VERSION ""

NS_ :

BS_:

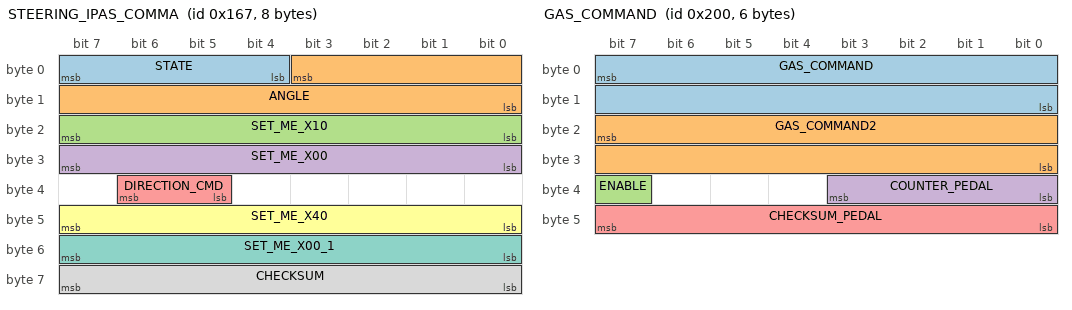
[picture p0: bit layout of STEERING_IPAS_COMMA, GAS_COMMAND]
BO_ 359 STEERING_IPAS_COMMA: 8 IPAS
 SG_ STATE : 7|4@0+ (1,0) [0|15] "" XXX
 SG_ ANGLE : 3|12@0- (1.5,0) [-510|510] "deg" XXX
 SG_ SET_ME_X10 : 23|8@0+ (1,0) [0|255] "" XXX
 SG_ SET_ME_X00 : 31|8@0+ (1,0) [0|255] "" XXX
 SG_ DIRECTION_CMD : 38|2@0+ (1,0) [0|3] "" XXX
 SG_ SET_ME_X40 : 47|8@0+ (1,0) [0|255] "" XXX
 SG_ SET_ME_X00_1 : 55|8@0+ (1,0) [0|255] "" XXX
 SG_ CHECKSUM : 63|8@0+ (1,0) [0|255] "" XXX

BO_ 512 GAS_COMMAND: 6 EON
 SG_ GAS_COMMAND : 7|16@0+ (0.159375,-75.555) [0|1] "" INTERCEPTOR
 SG_ GAS_COMMAND2 : 23|16@0+ (0.159375,-151.111) [0|1] "" INTERCEPTOR
 SG_ ENABLE : 39|1@0+ (1,0) [0|1] "" INTERCEPTOR
 SG_ COUNTER_PEDAL : 35|4@0+ (1,0) [0|15] "" INTERCEPTOR
 SG_ CHECKSUM_PEDAL : 47|8@0+ (1,0) [0|255] "" INTERCEPTOR

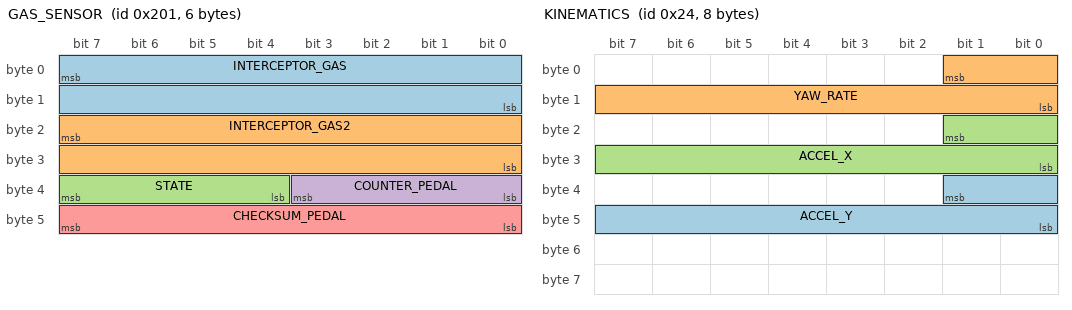
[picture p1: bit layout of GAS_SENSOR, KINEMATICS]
BO_ 513 GAS_SENSOR: 6 INTERCEPTOR
 SG_ INTERCEPTOR_GAS : 7|16@0+ (1,0) [0|1] "" EON
 SG_ INTERCEPTOR_GAS2 : 23|16@0+ (1,0) [0|1] "" EON
 SG_ STATE : 39|4@0+ (1,0) [0|15] "" EON
 SG_ COUNTER_PEDAL : 35|4@0+ (1,0) [0|15] "" EON
 SG_ CHECKSUM_PEDAL : 47|8@0+ (1,0) [0|255] "" EON

BO_ 35 SECONDARY_STEER_ANGLE: 8 XXX
 SG_ ZORRO_STEER : 7|24@0- (0.004901594652,0) [-500|500] "" XXX

BO_ 767 SDSU: 8 XXX
 SG_ FD_BUTTON : 7|1@0+ (1,0) [0|1] "" XXX

BO_ 36 KINEMATICS: 8 XXX
 SG_ ACCEL_Y : 33|10@0+ (0.03589,-18.375) [0|65535] "m/s^2" XXX
 SG_ YAW_RATE : 1|10@0+ (0.244,-125) [0|65535] "deg/s" XXX
 SG_ ACCEL_X : 17|10@0+ (0.03589,-18.375) [0|65535] "m/s^2" XXX

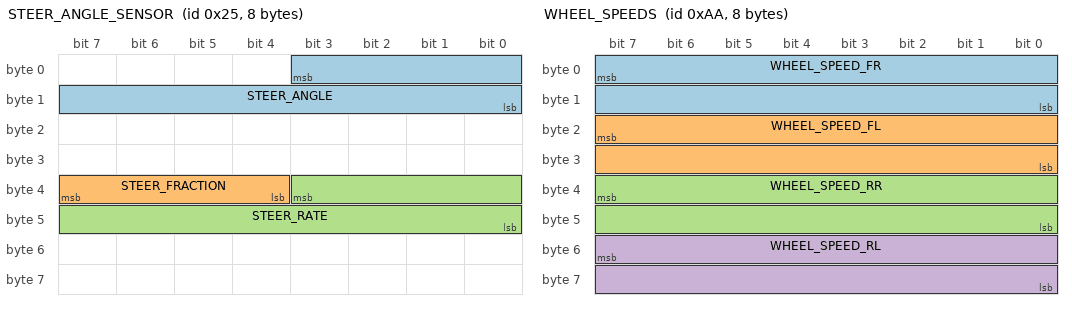
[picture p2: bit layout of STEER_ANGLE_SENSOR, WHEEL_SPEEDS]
BO_ 37 STEER_ANGLE_SENSOR: 8 XXX
 SG_ STEER_ANGLE : 3|12@0- (1.5,0) [-500|500] "deg" XXX
 SG_ STEER_FRACTION : 39|4@0- (0.1,0) [-0.7|0.7] "deg" XXX
 SG_ STEER_RATE : 35|12@0- (1,0) [-2000|2000] "deg/s" XXX

BO_ 166 BRAKE: 8 XXX
 SG_ BRAKE_AMOUNT : 7|8@0+ (1,0) [0|255] "" XXX
 SG_ BRAKE_PEDAL : 23|8@0+ (1,0) [0|255] "" XXX

BO_ 170 WHEEL_SPEEDS: 8 XXX
 SG_ WHEEL_SPEED_FR : 7|16@0+ (0.01,-67.67) [0|250] "km/h" XXX
 SG_ WHEEL_SPEED_FL : 23|16@0+ (0.01,-67.67) [0|250] "km/h" XXX
 SG_ WHEEL_SPEED_RR : 39|16@0+ (0.01,-67.67) [0|250] "km/h" XXX
 SG_ WHEEL_SPEED_RL : 55|16@0+ (0.01,-67.67) [0|250] "km/h" XXX

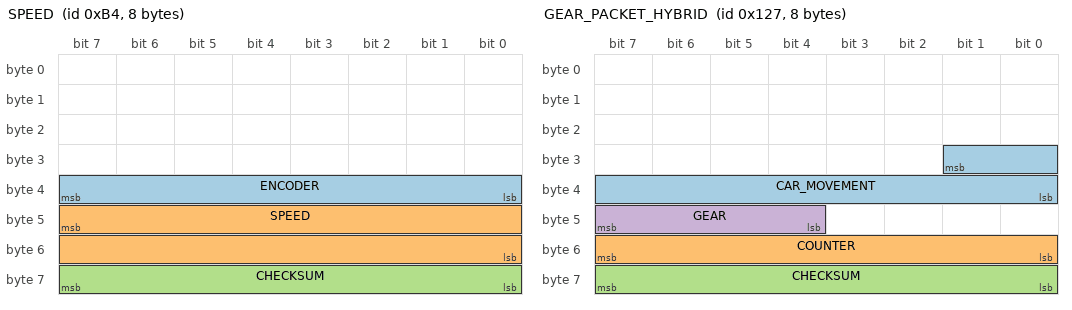
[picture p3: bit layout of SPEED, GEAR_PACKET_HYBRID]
BO_ 180 SPEED: 8 XXX
 SG_ ENCODER : 39|8@0+ (1,0) [0|255] "" XXX
 SG_ SPEED : 47|16@0+ (0.01,0) [0|250] "km/h" XXX
 SG_ CHECKSUM : 63|8@0+ (1,0) [0|255] "" XXX

BO_ 295 GEAR_PACKET_HYBRID: 8 XXX
 SG_ CAR_MOVEMENT : 25|10@0- (1,0) [0|255] "" XXX
 SG_ COUNTER : 55|8@0+ (1,0) [0|255] "" XXX
 SG_ CHECKSUM : 63|8@0+ (1,0) [0|255] "" XXX
 SG_ GEAR : 47|4@0+ (1,0) [0|15] "" XXX

BO_ 353 DSU_SPEED: 7 XXX
 SG_ FORWARD_SPEED : 15|16@0- (0.00390625,-30) [0|255] "km/h" XXX

BO_ 452 ENGINE_RPM: 8 CGW
 SG_ RPM : 7|16@0- (0.78125,0) [0|0] "rpm" SCS

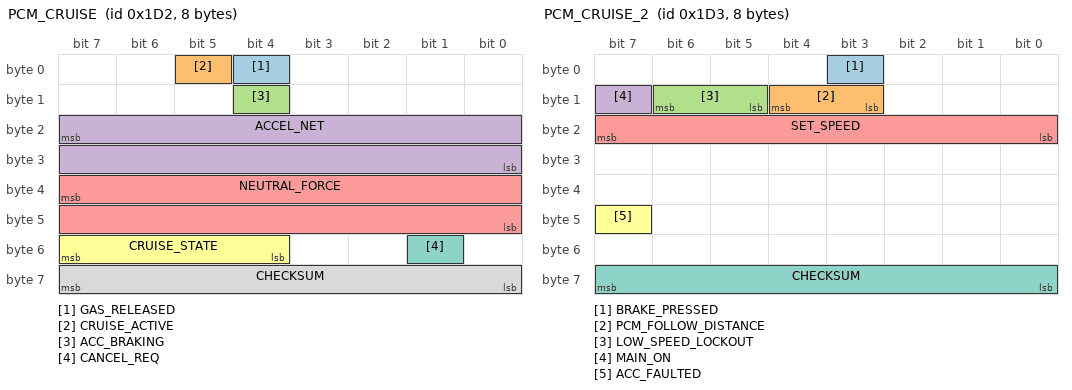
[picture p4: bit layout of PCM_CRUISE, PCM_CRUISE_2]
BO_ 466 PCM_CRUISE: 8 XXX
 SG_ GAS_RELEASED : 4|1@0+ (1,0) [0|1] "" XXX
 SG_ CRUISE_ACTIVE : 5|1@0+ (1,0) [0|1] "" XXX
 SG_ ACC_BRAKING : 12|1@0+ (1,0) [0|1] "" XXX
 SG_ ACCEL_NET : 23|16@0- (0.0009765625,0) [-20|20] "m/s^2" XXX
 SG_ NEUTRAL_FORCE : 39|16@0- (2,0) [-65536|65534] "N" XXX
 SG_ CRUISE_STATE : 55|4@0+ (1,0) [0|15] "" XXX
 SG_ CANCEL_REQ : 49|1@1+ (1,0) [0|1] "" XXX
 SG_ CHECKSUM : 63|8@0+ (1,0) [0|255] "" XXX

BO_ 467 PCM_CRUISE_2: 8 XXX
 SG_ BRAKE_PRESSED : 3|1@0+ (1,0) [0|1] "" XXX
 SG_ PCM_FOLLOW_DISTANCE : 12|2@0+ (1,0) [0|3] "" XXX
 SG_ LOW_SPEED_LOCKOUT : 14|2@0+ (1,0) [0|3] "" XXX
 SG_ MAIN_ON : 15|1@0+ (1,0) [0|1] "" XXX
 SG_ SET_SPEED : 23|8@0+ (1,0) [0|255] "km/h" XXX
 SG_ ACC_FAULTED : 47|1@0+ (1,0) [0|1] "" XXX
 SG_ CHECKSUM : 63|8@0+ (1,0) [0|255] "" XXX

BO_ 552 ACCELEROMETER: 8 XXX
 SG_ ACCEL_Z : 22|15@0- (1,0) [0|32767] "m/s^2" XXX
 SG_ ACCEL_X : 6|15@0- (0.001,0) [-20|20] "m/s^2" XXX

BO_ 560 BRAKE_2: 7 XXX
 SG_ BRAKE_PRESSED : 26|1@0+ (1,0) [0|1] "" XXX

BO_ 581 GAS_PEDAL_HYBRID: 8 XXX
 SG_ GAS_PEDAL : 23|8@0+ (0.005,0) [0|1] "" XXX

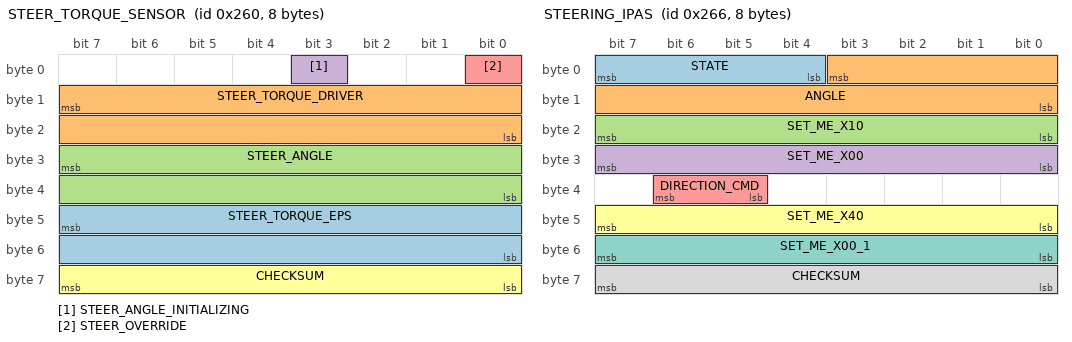
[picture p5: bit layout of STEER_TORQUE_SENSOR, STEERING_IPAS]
BO_ 608 STEER_TORQUE_SENSOR: 8 XXX
 SG_ STEER_TORQUE_EPS : 47|16@0- (1,0) [-32768|32767] "" XXX
 SG_ STEER_TORQUE_DRIVER : 15|16@0- (1,0) [-32768|32767] "" XXX
 SG_ STEER_ANGLE : 31|16@0- (0.0573,0) [-500|500] "" XXX
 SG_ STEER_ANGLE_INITIALIZING : 3|1@0+ (1,0) [0|1] "" XXX
 SG_ STEER_OVERRIDE : 0|1@0+ (1,0) [0|1] "" XXX
 SG_ CHECKSUM : 63|8@0+ (1,0) [0|255] "" XXX

BO_ 614 STEERING_IPAS: 8 IPAS
 SG_ STATE : 7|4@0+ (1,0) [0|15] "" XXX
 SG_ ANGLE : 3|12@0- (1.5,0) [-510|510] "deg" XXX
 SG_ SET_ME_X10 : 23|8@0+ (1,0) [0|255] "" XXX
 SG_ SET_ME_X00 : 31|8@0+ (1,0) [0|255] "" XXX
 SG_ DIRECTION_CMD : 38|2@0+ (1,0) [0|3] "" XXX
 SG_ SET_ME_X40 : 47|8@0+ (1,0) [0|255] "" XXX
 SG_ SET_ME_X00_1 : 55|8@0+ (1,0) [0|255] "" XXX
 SG_ CHECKSUM : 63|8@0+ (1,0) [0|255] "" XXX

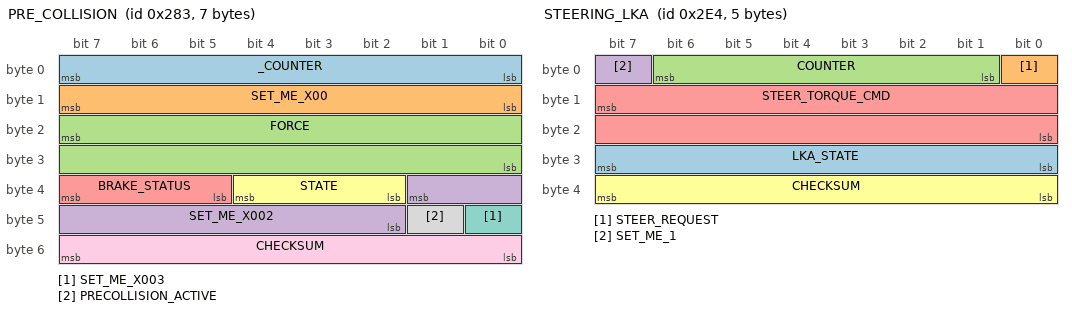
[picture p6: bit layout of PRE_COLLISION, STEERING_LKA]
BO_ 643 PRE_COLLISION: 7 DSU
 SG_ _COUNTER : 7|8@0+ (1,0) [0|255] "" XXX
 SG_ SET_ME_X00 : 15|8@0+ (1,0) [0|255] "" XXX
 SG_ FORCE : 23|16@0- (2,0) [0|255] "N" XXX
 SG_ SET_ME_X002 : 33|8@0+ (1,0) [0|3] "" XXX
 SG_ BRAKE_STATUS : 39|3@0+ (1,0) [0|255] "" XXX
 SG_ STATE : 36|3@0+ (1,0) [0|255] "" XXX
 SG_ SET_ME_X003 : 40|1@0+ (1,0) [0|1] "" XXX
 SG_ PRECOLLISION_ACTIVE : 41|1@0+ (1,0) [0|255] "" XXX
 SG_ CHECKSUM : 55|8@0+ (1,0) [0|255] "" XXX

BO_ 705 GAS_PEDAL: 8 XXX
 SG_ GAS_RELEASED : 3|1@0+ (1,0) [0|1] "" XXX
 SG_ GAS_PEDAL : 55|8@0+ (0.005,0) [0|1] "" XXX

BO_ 740 STEERING_LKA: 5 XXX
 SG_ LKA_STATE : 31|8@0+ (1,0) [0|255] "" XXX
 SG_ STEER_REQUEST : 0|1@0+ (1,0) [0|1] "" XXX
 SG_ COUNTER : 6|6@0+ (1,0) [0|63] "" XXX
 SG_ SET_ME_1 : 7|1@0+ (1,0) [0|1] "" XXX
 SG_ STEER_TORQUE_CMD : 15|16@0- (1,0) [0|65535] "" XXX
 SG_ CHECKSUM : 39|8@0+ (1,0) [0|255] "" XXX

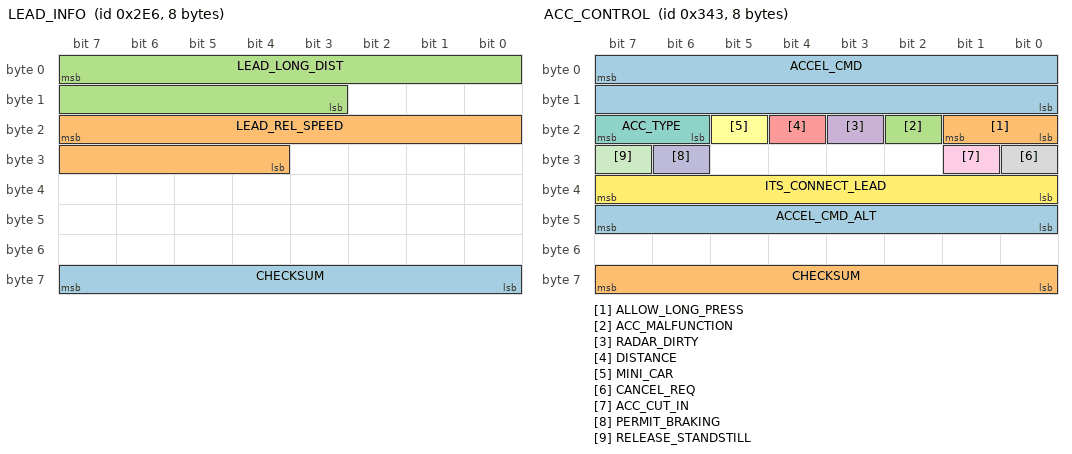
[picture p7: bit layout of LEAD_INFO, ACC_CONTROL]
BO_ 742 LEAD_INFO: 8 DSU
 SG_ CHECKSUM : 63|8@0+ (1,0) [0|255] "" HCU
 SG_ LEAD_REL_SPEED : 23|12@0- (0.025,0) [-100|100] "m/s" HCU
 SG_ LEAD_LONG_DIST : 7|13@0+ (0.05,0) [0|300] "m" HCU

BO_ 835 ACC_CONTROL: 8 DSU
 SG_ ACCEL_CMD : 7|16@0- (0.001,0) [-20|20] "m/s^2" HCU
 SG_ ALLOW_LONG_PRESS : 17|2@0+ (1,0) [0|2] "" XXX
 SG_ ACC_MALFUNCTION : 18|1@0+ (1,0) [0|0] "" XXX
 SG_ RADAR_DIRTY : 19|1@0+ (1,0) [0|1] "" XXX
 SG_ DISTANCE : 20|1@0+ (1,0) [0|1] "" XXX
 SG_ MINI_CAR : 21|1@0+ (1,0) [0|1] "" XXX
 SG_ ACC_TYPE : 23|2@0+ (1,0) [0|3] "" HCU
 SG_ CANCEL_REQ : 24|1@0+ (1,0) [0|1] "" HCU
 SG_ ACC_CUT_IN : 25|1@0+ (1,0) [0|1] "" XXX
 SG_ PERMIT_BRAKING : 30|1@0+ (1,0) [0|1] "" HCU
 SG_ RELEASE_STANDSTILL : 31|1@0+ (1,0) [0|1] "" HCU
 SG_ ITS_CONNECT_LEAD : 39|8@0+ (1,0) [0|1] "" Vector__XXX
 SG_ ACCEL_CMD_ALT : 47|8@0- (0.05,0) [0|0] "m/s^2" XXX
 SG_ CHECKSUM : 63|8@0+ (1,0) [0|255] "" XXX

BO_ 836 PRE_COLLISION_2: 8 DSU
 SG_ CHECKSUM : 63|8@0+ (1,0) [0|0] "" XXX

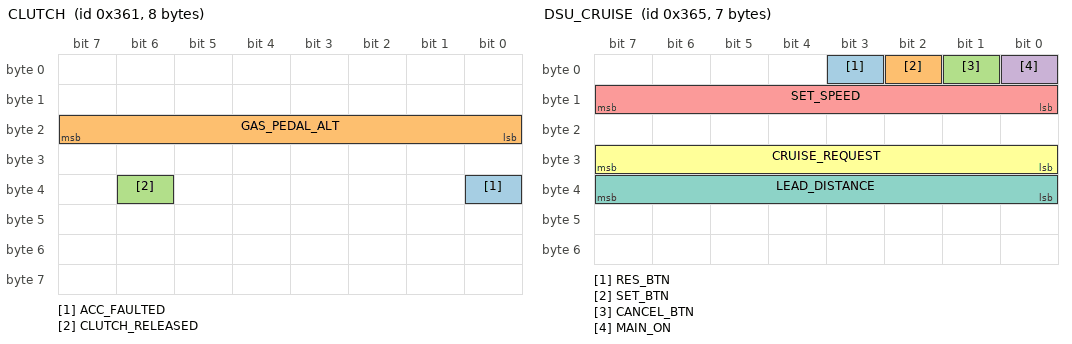
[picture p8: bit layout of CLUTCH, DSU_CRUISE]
BO_ 865 CLUTCH: 8 XXX
 SG_ ACC_FAULTED : 32|1@0+ (1,0) [0|1] "" XXX
 SG_ GAS_PEDAL_ALT : 23|8@0+ (0.005,0) [0|1] "" XXX
 SG_ CLUTCH_RELEASED : 38|1@0+ (1,0) [0|1] "" XXX

BO_ 869 DSU_CRUISE : 7 DSU
 SG_ RES_BTN : 3|1@0+ (1,0) [0|0] "" XXX
 SG_ SET_BTN : 2|1@0+ (1,0) [0|0] "" XXX
 SG_ CANCEL_BTN : 1|1@0+ (1,0) [0|0] "" XXX
 SG_ MAIN_ON : 0|1@0+ (1,0) [0|0] "" XXX
 SG_ SET_SPEED : 15|8@0+ (1,0) [0|0] "km/h" XXX
 SG_ CRUISE_REQUEST : 31|8@0+ (100,-12800) [0|0] "N" XXX
 SG_ LEAD_DISTANCE : 39|8@0+ (1,0) [0|0] "m" XXX

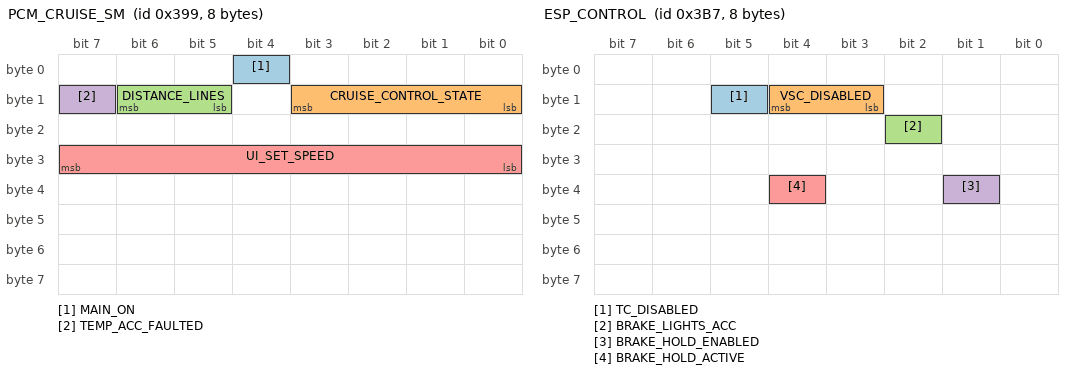
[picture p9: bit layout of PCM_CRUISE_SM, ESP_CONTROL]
BO_ 921 PCM_CRUISE_SM: 8 XXX
 SG_ MAIN_ON : 4|1@0+ (1,0) [0|1] "" XXX
 SG_ CRUISE_CONTROL_STATE : 11|4@0+ (1,0) [0|15] "" XXX
 SG_ DISTANCE_LINES : 14|2@0+ (1,0) [0|3] "" XXX
 SG_ TEMP_ACC_FAULTED : 15|1@0+ (1,0) [0|1] "" XXX
 SG_ UI_SET_SPEED : 31|8@0+ (1,0) [0|255] "" XXX

BO_ 951 ESP_CONTROL: 8 ESP
 SG_ TC_DISABLED : 13|1@0+ (1,0) [0|1] "" XXX
 SG_ VSC_DISABLED : 12|2@0+ (1,0) [0|1] "" XXX
 SG_ BRAKE_LIGHTS_ACC : 18|1@0+ (1,0) [0|1] "" XXX
 SG_ BRAKE_HOLD_ENABLED : 33|1@1+ (1,0) [0|1] "" XXX
 SG_ BRAKE_HOLD_ACTIVE : 36|1@0+ (1,0) [0|1] "" XXX

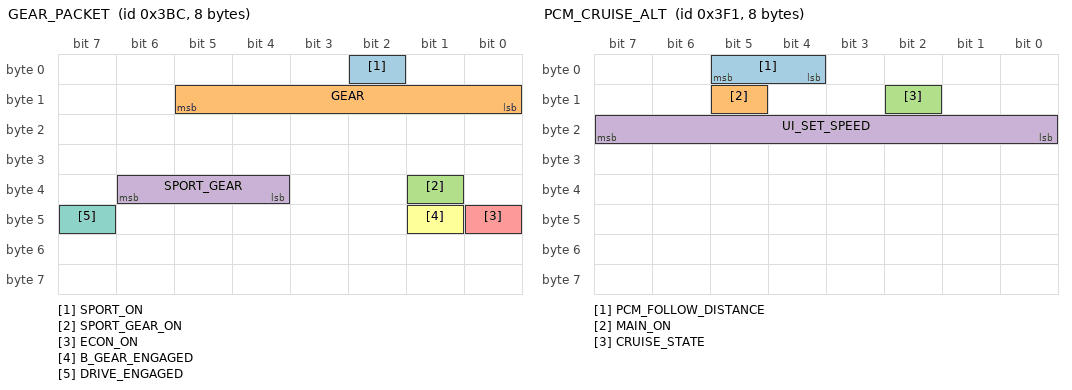
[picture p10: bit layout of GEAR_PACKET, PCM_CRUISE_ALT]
BO_ 956 GEAR_PACKET: 8 XXX
 SG_ SPORT_ON : 2|1@0+ (1,0) [0|1] "" XXX
 SG_ GEAR : 13|6@0+ (1,0) [0|63] "" XXX
 SG_ SPORT_GEAR_ON : 33|1@0+ (1,0) [0|1] "" XXX
 SG_ SPORT_GEAR : 38|3@0+ (1,0) [0|7] "" XXX
 SG_ ECON_ON : 40|1@0+ (1,0) [0|1] "" XXX
 SG_ B_GEAR_ENGAGED : 41|1@0+ (1,0) [0|1] "" XXX
 SG_ DRIVE_ENGAGED : 47|1@0+ (1,0) [0|1] "" XXX

BO_ 1005 REVERSE_CAMERA_STATE: 2 BGM
 SG_ REVERSE_CAMERA_GUIDELINES : 9|2@0+ (1,0) [1|3] "" XXX

BO_ 1009 PCM_CRUISE_ALT: 8 XXX
 SG_ PCM_FOLLOW_DISTANCE : 4|2@1+ (1,0) [0|3] "" XXX
 SG_ MAIN_ON : 13|1@0+ (1,0) [0|3] "" XXX
 SG_ CRUISE_STATE : 10|1@0+ (1,0) [0|1] "" XXX
 SG_ UI_SET_SPEED : 23|8@0+ (1,0) [0|255] "mph" XXX

BO_ 1020 SOLAR_SENSOR: 8 XXX
 SG_ LUX_SENSOR : 55|13@0+ (1,0) [0|0] "" XXX

BO_ 1041 PCS_HUD: 8 DSU
 SG_ PCS_INDICATOR : 7|2@0+ (1,0) [0|3] "" XXX
 SG_ FCW : 4|1@0+ (1,0) [0|1] "" XXX
 SG_ SET_ME_X20 : 15|8@0+ (1,0) [0|1] "" XXX
 SG_ PCS_DUST : 34|1@0+ (1,0) [0|0] "" XXX
 SG_ PCS_TEMP : 35|1@0+ (1,0) [0|0] "" XXX
 SG_ PCS_DUST2 : 41|1@0+ (1,0) [0|0] "" XXX
 SG_ PCS_TEMP2 : 42|1@0+ (1,0) [0|0] "" XXX
 SG_ SET_ME_X10 : 39|8@0+ (1,0) [0|1] "" XXX
 SG_ PCS_OFF : 40|1@0+ (1,0) [0|0] "" XXX
 SG_ FRD_ADJ : 53|3@0+ (1,0) [0|0] "" XXX
 SG_ PCS_SENSITIVITY : 55|8@0+ (1,0) [0|1] "" XXX

BO_ 1042 LKAS_HUD: 8 DSU
 SG_ BARRIERS : 1|2@0+ (1,0) [0|3] "" XXX
 SG_ RIGHT_LINE : 3|2@0+ (1,0) [0|3] "" XXX
 SG_ LEFT_LINE : 5|2@0+ (1,0) [0|3] "" XXX
 SG_ LKAS_STATUS : 7|2@0+ (1,0) [0|3] "" XXX
 SG_ LDA_ALERT : 9|2@0+ (1,0) [0|3] "" XXX
 SG_ LDW_EXIST : 10|1@0+ (1,0) [0|1] "" XXX
 SG_ TWO_BEEPS : 12|1@0+ (1,0) [0|1] "" XXX
 SG_ ADJUSTING_CAMERA : 13|1@0+ (1,0) [0|1] "" XXX
 SG_ LDA_UNAVAILABLE_QUIET : 14|1@0+ (1,0) [0|1] "" XXX
 SG_ LDA_MALFUNCTION : 15|1@0+ (1,0) [0|1] "" XXX
 SG_ LDA_UNAVAILABLE : 16|1@0+ (1,0) [0|1] "" XXX
 SG_ LDA_SENSITIVITY : 18|2@0+ (1,0) [0|3] "" XXX
 SG_ LDA_SA_TOGGLE : 20|2@0+ (1,0) [0|3] "" XXX
 SG_ LDA_MESSAGES : 23|3@0+ (1,0) [0|1] "" XXX
 SG_ LDA_ON_MESSAGE : 31|2@0+ (1,0) [0|3] "" XXX
 SG_ REPEATED_BEEPS : 32|1@0+ (1,0) [0|1] "" XXX
 SG_ LANE_SWAY_TOGGLE : 43|1@0+ (1,0) [0|1] "" XXX
 SG_ LANE_SWAY_SENSITIVITY : 45|2@0+ (1,0) [0|3] "" XXX
 SG_ TAKE_CONTROL : 46|1@0+ (1,0) [0|1] "" XXX
 SG_ LDA_FRONT_CAMERA_BLOCKED : 47|1@0+ (1,0) [0|1] "" XXX
 SG_ LANE_SWAY_BUZZER : 50|2@0+ (1,0) [0|0] "" XXX
 SG_ LANE_SWAY_FLD : 53|3@0+ (1,0) [0|7] "" XXX
 SG_ LANE_SWAY_WARNING : 55|2@0+ (1,0) [0|3] "" XXX
 SG_ SET_ME_X01 : 42|1@0+ (1,0) [0|1] "" XXX
 SG_ SET_ME_X02 : 63|8@0+ (1,0) [0|1] "" XXX

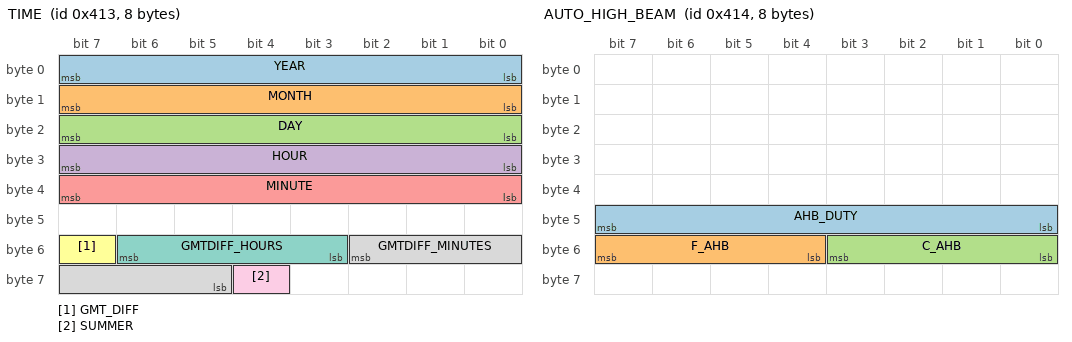
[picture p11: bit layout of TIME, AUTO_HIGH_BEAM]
BO_ 1043 TIME : 8 CGW
 SG_ YEAR : 7|8@0+ (1,0) [0|0] "year" XXX
 SG_ MONTH : 15|8@0+ (1,0) [0|0] "month" XXX
 SG_ DAY : 23|8@0+ (1,0) [0|0] "day" XXX
 SG_ HOUR : 31|8@0+ (1,0) [0|0] "hour" XXX
 SG_ MINUTE : 39|8@0+ (1,0) [0|0] "minute" XXX
 SG_ GMT_DIFF : 55|1@0+ (1,0) [0|0] "" XXX
 SG_ GMTDIFF_HOURS : 54|4@0+ (1,0) [0|0] "hours" XXX
 SG_ GMTDIFF_MINUTES : 50|6@0+ (1,0) [0|0] "minutes" XXX
 SG_ SUMMER : 60|1@0+ (1,0) [0|0] "" XXX

BO_ 1044 AUTO_HIGH_BEAM: 8 FCM
 SG_ AHB_DUTY : 47|8@0+ (0.5,0) [0|0] "%" Vector__XXX
 SG_ F_AHB : 55|4@0+ (1,0) [0|0] "" Vector__XXX
 SG_ C_AHB : 51|4@0+ (1,0) [0|0] "" Vector__XXX

BO_ 1083 AUTOPARK_STATUS: 8 IPAS
 SG_ STATE : 7|4@0+ (1,0) [0|15] "" XXX

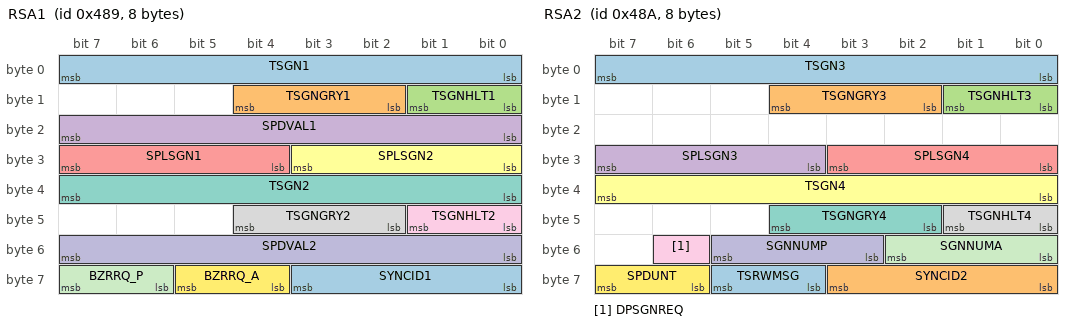
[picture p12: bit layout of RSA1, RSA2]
BO_ 1161 RSA1: 8 FCM
 SG_ TSGN1 : 7|8@0+ (1,0) [0|0] "" XXX
 SG_ TSGNGRY1 : 12|3@0+ (1,0) [0|0] "" XXX
 SG_ TSGNHLT1 : 9|2@0+ (1,0) [0|0] "" XXX
 SG_ SPDVAL1 : 23|8@0+ (1,0) [0|0] "km/h" XXX
 SG_ SPLSGN1 : 31|4@0+ (1,0) [0|0] "" XXX
 SG_ SPLSGN2 : 27|4@0+ (1,0) [0|0] "" XXX
 SG_ TSGN2 : 39|8@0+ (1,0) [0|0] "" XXX
 SG_ TSGNGRY2 : 44|3@0+ (1,0) [0|0] "" XXX
 SG_ TSGNHLT2 : 41|2@0+ (1,0) [0|0] "" XXX
 SG_ SPDVAL2 : 55|8@0+ (1,0) [0|0] "" XXX
 SG_ BZRRQ_P : 63|2@0+ (1,0) [0|0] "" XXX
 SG_ BZRRQ_A : 61|2@0+ (1,0) [0|0] "" XXX
 SG_ SYNCID1 : 59|4@0+ (1,0) [0|0] "" XXX

BO_ 1162 RSA2: 8 FCM
 SG_ TSGN3 : 7|8@0+ (1,0) [0|0] "" XXX
 SG_ TSGNGRY3 : 12|3@0+ (1,0) [0|0] "" XXX
 SG_ TSGNHLT3 : 9|2@0+ (1,0) [0|0] "" XXX
 SG_ SPLSGN3 : 31|4@0+ (1,0) [0|0] "" XXX
 SG_ SPLSGN4 : 27|4@0+ (1,0) [0|0] "" XXX
 SG_ TSGN4 : 39|8@0+ (1,0) [0|0] "" XXX
 SG_ TSGNGRY4 : 44|3@0+ (1,0) [0|0] "" XXX
 SG_ TSGNHLT4 : 41|2@0+ (1,0) [0|0] "" XXX
 SG_ DPSGNREQ : 54|1@0+ (1,0) [0|0] "" XXX
 SG_ SGNNUMP : 53|3@0+ (1,0) [0|0] "" XXX
 SG_ SGNNUMA : 50|3@0+ (1,0) [0|0] "" XXX
 SG_ SPDUNT : 63|2@0+ (1,0) [0|0] "" XXX
 SG_ TSRWMSG : 61|2@0+ (1,0) [0|0] "" XXX
 SG_ SYNCID2 : 59|4@0+ (1,0) [0|0] "" XXX

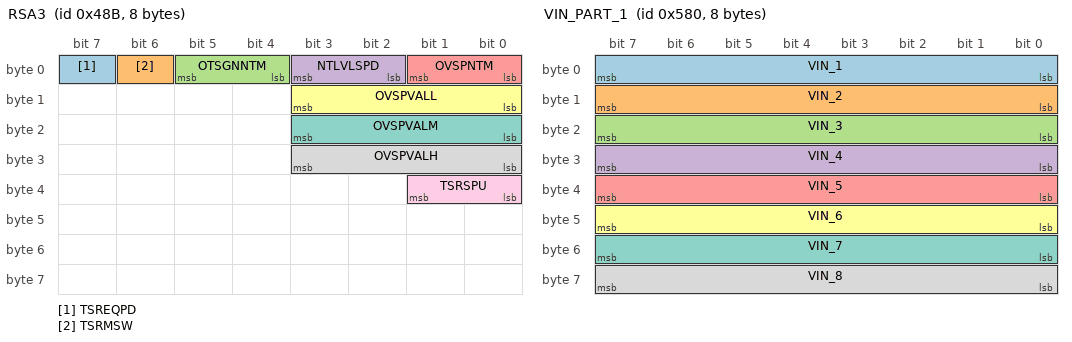
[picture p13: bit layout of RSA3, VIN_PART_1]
BO_ 1163 RSA3: 8 FCM
 SG_ TSREQPD : 7|1@0+ (1,0) [0|0] "" XXX
 SG_ TSRMSW : 6|1@0+ (1,0) [0|0] "" XXX
 SG_ OTSGNNTM : 5|2@0+ (1,0) [0|0] "" XXX
 SG_ NTLVLSPD : 3|2@0+ (1,0) [0|0] "" XXX
 SG_ OVSPNTM : 1|2@0+ (1,0) [0|0] "" XXX
 SG_ OVSPVALL : 11|4@0+ (1,-5) [0|0] "" XXX
 SG_ OVSPVALM : 19|4@0+ (1,-5) [0|0] "" XXX
 SG_ OVSPVALH : 27|4@0+ (1,-5) [0|0] "" XXX
 SG_ TSRSPU : 33|2@0+ (1,0) [0|0] "" XXX

BO_ 1408 VIN_PART_1: 8 CGW
 SG_ VIN_1 : 7|8@0+ (1,0) [0|0] "" XXX
 SG_ VIN_2 : 15|8@0+ (1,0) [0|0] "" XXX
 SG_ VIN_3 : 23|8@0+ (1,0) [0|0] "" XXX
 SG_ VIN_4 : 31|8@0+ (1,0) [0|0] "" XXX
 SG_ VIN_5 : 39|8@0+ (1,0) [0|0] "" XXX
 SG_ VIN_6 : 47|8@0+ (1,0) [0|0] "" XXX
 SG_ VIN_7 : 55|8@0+ (1,0) [0|0] "" XXX
 SG_ VIN_8 : 63|8@0+ (1,0) [0|0] "" XXX

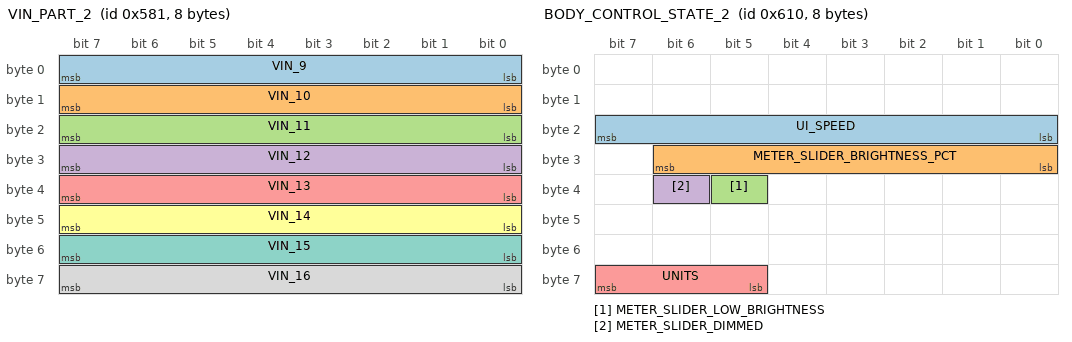
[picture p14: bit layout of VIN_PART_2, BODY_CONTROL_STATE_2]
BO_ 1409 VIN_PART_2: 8 CGW
 SG_ VIN_9 : 7|8@0+ (1,0) [0|0] "" XXX
 SG_ VIN_10 : 15|8@0+ (1,0) [0|0] "" XXX
 SG_ VIN_11 : 23|8@0+ (1,0) [0|0] "" XXX
 SG_ VIN_12 : 31|8@0+ (1,0) [0|0] "" XXX
 SG_ VIN_13 : 39|8@0+ (1,0) [0|0] "" XXX
 SG_ VIN_14 : 47|8@0+ (1,0) [0|0] "" XXX
 SG_ VIN_15 : 55|8@0+ (1,0) [0|0] "" XXX
 SG_ VIN_16 : 63|8@0+ (1,0) [0|0] "" XXX

BO_ 1410 VIN_PART_3: 8 CGW
 SG_ VIN_17 : 7|8@0+ (1,0) [0|0] "" XXX

BO_ 1552 BODY_CONTROL_STATE_2: 8 XXX
 SG_ UI_SPEED : 23|8@0+ (1,0) [0|255] "" XXX
 SG_ METER_SLIDER_BRIGHTNESS_PCT : 30|7@0+ (1,0) [12|100] "%" XXX
 SG_ METER_SLIDER_LOW_BRIGHTNESS : 37|1@0+ (1,0) [0|1] "" XXX
 SG_ METER_SLIDER_DIMMED : 38|1@0+ (1,0) [0|1] "" XXX
 SG_ UNITS : 63|3@0+ (1,0) [1|4] "" XXX

BO_ 1553 UI_SETTING: 8 XXX
 SG_ UNITS : 26|2@0+ (1,0) [0|3] "" XXX
 SG_ ODOMETER : 39|32@0+ (1,0) [0|1048575] "" XXX
BO_ 1556 BLINKERS_STATE: 8 XXX
 SG_ TURN_SIGNALS : 29|2@0+ (1,0) [0|3] "" XXX
 SG_ HAZARD_LIGHT : 27|1@0+ (1,0) [0|1] "" XXX

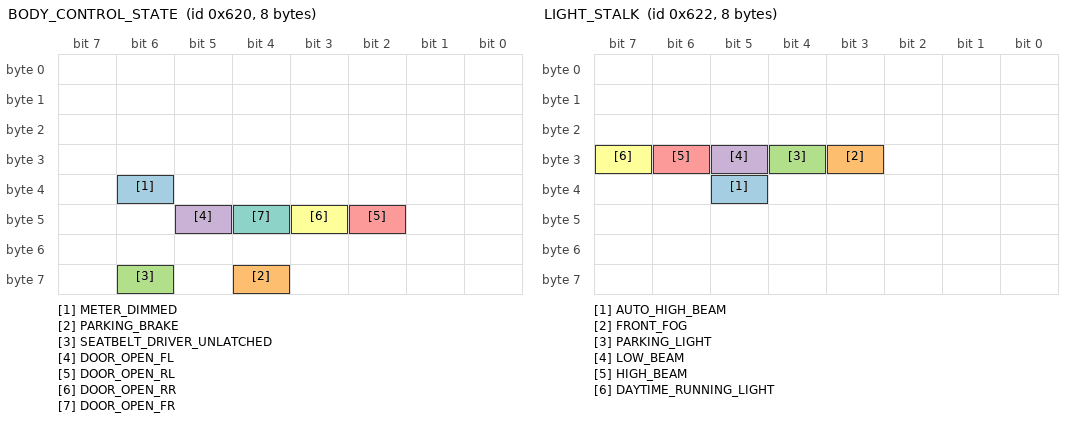
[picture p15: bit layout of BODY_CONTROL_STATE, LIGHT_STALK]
BO_ 1568 BODY_CONTROL_STATE: 8 XXX
 SG_ METER_DIMMED : 38|1@0+ (1,0) [0|1] "" XXX
 SG_ PARKING_BRAKE : 60|1@0+ (1,0) [0|1] "" XXX
 SG_ SEATBELT_DRIVER_UNLATCHED : 62|1@0+ (1,0) [0|1] "" XXX
 SG_ DOOR_OPEN_FL : 45|1@0+ (1,0) [0|1] "" XXX
 SG_ DOOR_OPEN_RL : 42|1@0+ (1,0) [0|1] "" XXX
 SG_ DOOR_OPEN_RR : 43|1@0+ (1,0) [0|1] "" XXX
 SG_ DOOR_OPEN_FR : 44|1@0+ (1,0) [0|1] "" XXX

BO_ 1570 LIGHT_STALK: 8 SCM
 SG_ AUTO_HIGH_BEAM : 37|1@0+ (1,0) [0|1] "" XXX
 SG_ FRONT_FOG : 27|1@0+ (1,0) [0|1] "" XXX
 SG_ PARKING_LIGHT : 28|1@0+ (1,0) [0|1] "" XXX
 SG_ LOW_BEAM : 29|1@0+ (1,0) [0|1] "" XXX
 SG_ HIGH_BEAM : 30|1@0+ (1,0) [0|1] "" XXX
 SG_ DAYTIME_RUNNING_LIGHT : 31|1@0+ (1,0) [0|1] "" XXX

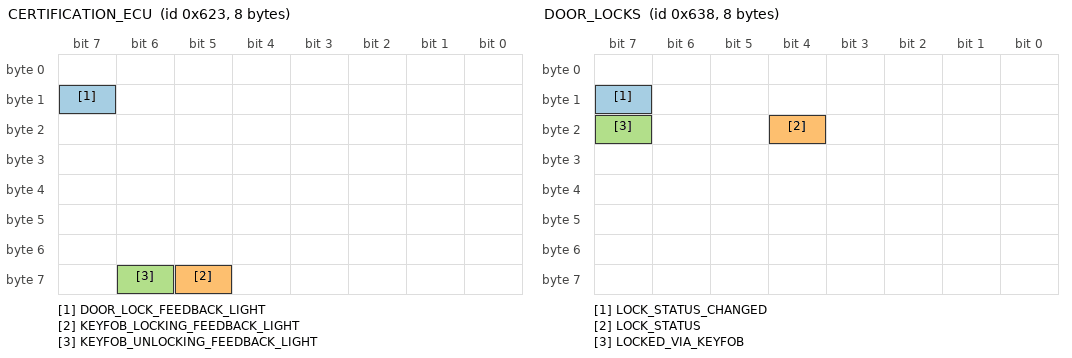
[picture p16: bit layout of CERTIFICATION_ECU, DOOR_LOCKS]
BO_ 1571 CERTIFICATION_ECU: 8 CGW
 SG_ DOOR_LOCK_FEEDBACK_LIGHT : 15|1@0+ (1,0) [0|0] "" XXX
 SG_ KEYFOB_LOCKING_FEEDBACK_LIGHT : 61|1@0+ (1,0) [0|0] "" XXX
 SG_ KEYFOB_UNLOCKING_FEEDBACK_LIGHT : 62|1@0+ (1,0) [0|0] "" XXX

BO_ 1592 DOOR_LOCKS: 8 XXX
 SG_ LOCK_STATUS_CHANGED : 15|1@0+ (1,0) [0|1] "" XXX
 SG_ LOCK_STATUS : 20|1@0+ (1,0) [0|1] "" XXX
 SG_ LOCKED_VIA_KEYFOB : 23|1@0+ (1,0) [0|1] "" XXX

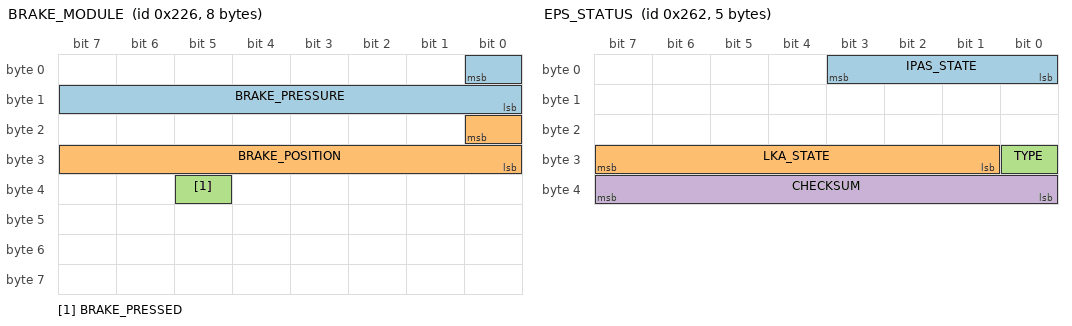
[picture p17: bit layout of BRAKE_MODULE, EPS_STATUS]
BO_ 550 BRAKE_MODULE: 8 XXX
 SG_ BRAKE_PRESSURE : 0|9@0+ (1,0) [0|511] "" XXX
 SG_ BRAKE_POSITION : 16|9@0+ (1,0) [0|511] "" XXX
 SG_ BRAKE_PRESSED : 37|1@0+ (1,0) [0|1] "" XXX

BO_ 610 EPS_STATUS: 5 EPS
 SG_ IPAS_STATE : 3|4@0+ (1,0) [0|15] "" XXX
 SG_ LKA_STATE : 31|7@0+ (1,0) [0|127] "" XXX
 SG_ TYPE : 24|1@0+ (1,0) [0|1] "" XXX
 SG_ CHECKSUM : 39|8@0+ (1,0) [0|255] "" XXX

BU_: XXX DSU HCU EPS IPAS CGW BGM

VAL_ 34 IPMA_PCAN_DataRangeCheck 1 "Fault Present" 0 "No Fault";
VAL_ 34 IPMA_PCAN_MissingMsg 1 "Fault Present" 0 "No Fault ";
VAL_ 34 VINSignalCompareFailure 1 "Fault Present" 0 "No Fault";
VAL_ 34 ModuleNotConfiguredError 1 "Fault Present" 0 "No Fault";
VAL_ 34 CarCfgNotConfiguredError 1 "Fault Present" 0 "No Fault";
VAL_ 33 Active_Flt_Latched_byte7_bit7 1 "Fault Present" 0 "No Fault";
VAL_ 33 Active_Flt_Latched_byte7_bit6 1 "Fault Present" 0 "No Fault";
VAL_ 33 Active_Flt_Latched_byte7_bit5 1 "Fault Present" 0 "No Fault";
VAL_ 33 Active_Flt_Latched_byte7_bit4 1 "Fault Present" 0 "No Fault";
VAL_ 33 ARMtoDSPChksumFault 1 "Fault Present" 0 "No Fault";
VAL_ 33 DSPtoArmChksumFault 1 "Fault Present" 0 "No Fault";
VAL_ 33 HostToArmChksumFault 1 "Fault Present" 0 "No Fault";
VAL_ 33 ARMtoHostChksumFault 1 "Fault Present" 0 "No Fault";
VAL_ 33 LoopBWOutOfRange 1 "Fault Present" 0 "No Fault";
VAL_ 33 DSPOverrunFault 1 "Fault Present" 0 "No Fault";
VAL_ 33 Active_Flt_Latched_byte6_bit5 1 "Fault Present" 0 "No Fault";
VAL_ 33 TuningSensitivityFault 1 "Fault Present" 0 "No Fault";
VAL_ 33 SaturatedTuningFreqFault 1 "Fault Present" 0 "No Fault";
VAL_ 33 LocalOscPowerFault 1 "Fault Present" 0 "No Fault";
VAL_ 33 TransmitterPowerFault 1 "Fault Present" 0 "No Fault";
VAL_ 33 Active_Flt_Latched_byte6_bit0 1 "Fault Present" 0 "No Fault";
VAL_ 33 Active_Flt_Latched_byte5_bit7 1 "Fault Present" 0 "No Fault";
VAL_ 33 Active_Flt_Latched_byte5_bit6 1 "Fault Present" 0 "No Fault";
VAL_ 33 XCVRDeviceSPIFault 1 "Fault Present" 0 "No Fault";
VAL_ 33 FreqSynthesizerSPIFault 1 "Fault Present" 0 "No Fault";
VAL_ 33 AnalogConverterDevicSPIFault 1 "Fault Present" 0 "No Fault";
VAL_ 33 SidelobeBlockage 1 "Fault Present" 0 "No Fault";
VAL_ 33 Active_Flt_Latched_byte5_bit1 1 "Fault Present" 0 "No Fault";
VAL_ 33 MNRBlocked 1 "Fault Present" 0 "No Fault";
VAL_ 33 ECUTempHighFault 1 "Fault Present" 0 "No Fault";
VAL_ 33 TransmitterTempHighFault 1 "Fault Present" 0 "No Fault";
VAL_ 33 AlignmentRoutineFailedFault 1 "Fault Present" 0 "No Fault";
VAL_ 33 UnreasonableRadarData 1 "Fault Present" 0 "No Fault";
VAL_ 33 MicroprocessorTempHighFault 1 "Fault Present" 0 "No Fault";
VAL_ 33 VerticalAlignmentOutOfRange 1 "Fault Present" 0 "No Fault";
VAL_ 33 HorizontalAlignmentOutOfRange 1 "Fault Present" 0 "No Fault";
VAL_ 33 FactoryAlignmentMode 1 "Fault Present" 0 "No Fault";
VAL_ 33 BatteryLowFault 1 "Fault Present" 0 "No Fault";
VAL_ 33 BatteryHighFault 1 "Fault Present" 0 "No Fault";
VAL_ 33 v_1p25SupplyOutOfRange 1 "Fault Present" 0 "No Fault";
VAL_ 33 Active_Flt_Latched_byte3_bit4 1 "Fault Present" 0 "No Fault";
VAL_ 33 ThermistorOutOfRange 1 "Fault Present" 0 "No Fault";
VAL_ 33 v_3p3DACSupplyOutOfRange 1 "Fault Present" 0 "No Fault";
VAL_ 33 v_3p3RAWSupplyOutOfRange 1 "Fault Present" 0 "No Fault";
VAL_ 33 v_5_SupplyOutOfRange 1 "Fault Present" 0 "No Fault";
VAL_ 33 TransmitterIDFault 1 "Fault Present" 0 "No Fault";
VAL_ 33 Active_Flt_Latched_byte2_bit6 1 "Fault Present" 0 "No Fault";
VAL_ 33 Active_Flt_Latched_byte2_bit5 1 "Fault Present" 0 "No Fault";
VAL_ 33 Active_Flt_Latched_byte2_bit4 1 "Fault Present" 0 "No Fault";
VAL_ 33 Active_Flt_Latched_byte2_bit3 1 "Fault Present" 0 "No Fault";
VAL_ 33 Active_Flt_Latched_byte2_bit2 1 "Fault Present" 0 "No Fault";
VAL_ 33 PCANMissingMsgFault 1 "Fault Present" 0 "No Fault";
VAL_ 33 PCANBusOff 1 "Fault Present" 0 "No Fault";
VAL_ 33 Active_Flt_Latched_byte1_bit7 1 "Fault Present" 0 "No Fault";
VAL_ 33 Active_Flt_Latched_byte1_bit6 1 "Fault Present" 0 "No Fault";
VAL_ 33 InstructionSetCheckFault 1 "Fault Present" 0 "No Fault";
VAL_ 33 StackOverflowFault 1 "Fault Present" 0 "No Fault";
VAL_ 33 WatchdogFault 1 "Fault Present" 0 "No Fault";
VAL_ 33 PLLLockFault 1 "Fault Present" 0 "No Fault";
VAL_ 33 Active_Flt_Latched_byte1_bit1 1 "Fault Present" 0 "No Fault";
VAL_ 33 RAMMemoryTestFault 1 "Fault Present" 0 "No Fault";
VAL_ 33 USCValidationFault 1 "Fault Present" 0 "No Fault";
VAL_ 33 Active_Flt_Latched_byte0_bit6 1 "Fault Present" 0 "No Fault";
VAL_ 33 Active_Flt_Latched_byte0_bit5 1 "Fault Present" 0 "No Fault";
VAL_ 33 Active_Flt_Latched_byte0_bit4 1 "Fault Present" 0 "No Fault";
VAL_ 33 Active_Flt_Latched_byte0_bit3 1 "Fault Present" 0 "No Fault";
VAL_ 33 KeepAliveChecksumFault 1 "Fault Present" 0 "No Fault";
VAL_ 33 ProgramCalibrationFlashChecksum 1 "Fault Present" 0 "No Fault";
VAL_ 33 ApplicationFlashChecksumFault 1 "Fault Present" 0 "No Fault";
VAL_ 371 CAN_AUTO_ALIGN_HANGLE_QF 3 "Accurate" 2 "Innacurate" 1 "Temporarily undefined" 0 "Undefined";
VAL_ 371 CAN_ALIGNMENT_STATUS 15 "Undefined_2" 14 "Undefined_1" 13 "Low Amplitude (Flat-plate only)" 12 "No Peak (Flat-plate only)" 11 "Fail Ver and Hor OutOfRange" 10 "Fail Vertical Align OutOfRange" 9 "Fail Horizontal Align OutOfRange" 8 "Fail Time Out" 7 "Fail Only Right Target Found" 6 "Fail Only Left Target Found" 5 "Fail Variance Too Large" 4 "Fail Deviation Too Large" 3 "Fail No Target" 2 "Success" 1 "Busy" 0 "Off";
VAL_ 371 CAN_ALIGNMENT_STATE 6 "Static alignment flat-plate" 5 "Static alignment 2-target" 4 "Static alignment 1-target" 3 "Service alignment" 2 "Short track alignment" 1 "Auto alignment" 0 "Off";
VAL_ 291 CAN_DET_CONFID_AZIMUTH_04 3 "Low" 2 "Medium_Low" 1 "Medium_High" 0 "High";
VAL_ 351 CAN_DET_CONFID_AZIMUTH_64 3 "Low" 2 "Medium_Low" 1 "Medium_High" 0 "High";
VAL_ 350 CAN_DET_CONFID_AZIMUTH_63 3 "Low" 2 "Medium_Low" 1 "Medium_High" 0 "High";
VAL_ 349 CAN_DET_CONFID_AZIMUTH_62 3 "Low" 2 "Medium_Low" 1 "Medium_High" 0 "High";
VAL_ 348 CAN_DET_CONFID_AZIMUTH_61 3 "Low" 2 "Medium_Low" 1 "Medium_High" 0 "High";
VAL_ 347 CAN_DET_CONFID_AZIMUTH_60 3 "Low" 2 "Medium_Low" 1 "Medium_High" 0 "High";
VAL_ 346 CAN_DET_CONFID_AZIMUTH_59 3 "Low" 2 "Medium_Low" 1 "Medium_High" 0 "High";
VAL_ 345 CAN_DET_CONFID_AZIMUTH_58 3 "Low" 2 "Medium_Low" 1 "Medium_High" 0 "High";
VAL_ 344 CAN_DET_CONFID_AZIMUTH_57 3 "Low" 2 "Medium_Low" 1 "Medium_High" 0 "High";
VAL_ 343 CAN_DET_CONFID_AZIMUTH_56 3 "Low" 2 "Medium_Low" 1 "Medium_High" 0 "High";
VAL_ 342 CAN_DET_CONFID_AZIMUTH_55 3 "Low" 2 "Medium_Low" 1 "Medium_High" 0 "High";
VAL_ 335 CAN_DET_CONFID_AZIMUTH_48 3 "Low" 2 "Medium_Low" 1 "Medium_High" 0 "High";
VAL_ 334 CAN_DET_CONFID_AZIMUTH_47 3 "Low" 2 "Medium_Low" 1 "Medium_High" 0 "High";
VAL_ 333 CAN_DET_CONFID_AZIMUTH_46 3 "Low" 2 "Medium_Low" 1 "Medium_High" 0 "High";
VAL_ 332 CAN_DET_CONFID_AZIMUTH_45 3 "Low" 2 "Medium_Low" 1 "Medium_High" 0 "High";
VAL_ 331 CAN_DET_CONFID_AZIMUTH_44 3 "Low" 2 "Medium_Low" 1 "Medium_High" 0 "High";
VAL_ 330 CAN_DET_CONFID_AZIMUTH_43 3 "Low" 2 "Medium_Low" 1 "Medium_High" 0 "High";
VAL_ 329 CAN_DET_CONFID_AZIMUTH_42 3 "Low" 2 "Medium_Low" 1 "Medium_High" 0 "High";
VAL_ 328 CAN_DET_CONFID_AZIMUTH_41 3 "Low" 2 "Medium_Low" 1 "Medium_High" 0 "High";
VAL_ 327 CAN_DET_CONFID_AZIMUTH_40 3 "Low" 2 "Medium_Low" 1 "Medium_High" 0 "High";
VAL_ 325 CAN_DET_CONFID_AZIMUTH_38 3 "Low" 2 "Medium_Low" 1 "Medium_High" 0 "High";
VAL_ 324 CAN_DET_CONFID_AZIMUTH_37 3 "Low" 2 "Medium_Low" 1 "Medium_High" 0 "High";
VAL_ 323 CAN_DET_CONFID_AZIMUTH_36 3 "Low" 2 "Medium_Low" 1 "Medium_High" 0 "High";
VAL_ 322 CAN_DET_CONFID_AZIMUTH_35 3 "Low" 2 "Medium_Low" 1 "Medium_High" 0 "High";
VAL_ 321 CAN_DET_CONFID_AZIMUTH_34 3 "Low" 2 "Medium_Low" 1 "Medium_High" 0 "High";
VAL_ 320 CAN_DET_CONFID_AZIMUTH_33 3 "Low" 2 "Medium_Low" 1 "Medium_High" 0 "High";
VAL_ 319 CAN_DET_CONFID_AZIMUTH_32 3 "Low" 2 "Medium_Low" 1 "Medium_High" 0 "High";
VAL_ 318 CAN_DET_CONFID_AZIMUTH_31 3 "Low" 2 "Medium_Low" 1 "Medium_High" 0 "High";
VAL_ 317 CAN_DET_CONFID_AZIMUTH_30 3 "Low" 2 "Medium_Low" 1 "Medium_High" 0 "High";
VAL_ 316 CAN_DET_CONFID_AZIMUTH_29 3 "Low" 2 "Medium_Low" 1 "Medium_High" 0 "High";
VAL_ 314 CAN_DET_CONFID_AZIMUTH_27 3 "Low" 2 "Medium_Low" 1 "Medium_High" 0 "High";
VAL_ 313 CAN_DET_CONFID_AZIMUTH_26 3 "Low" 2 "Medium_Low" 1 "Medium_High" 0 "High";
VAL_ 312 CAN_DET_CONFID_AZIMUTH_25 3 "Low" 2 "Medium_Low" 1 "Medium_High" 0 "High";
VAL_ 311 CAN_DET_CONFID_AZIMUTH_24 3 "Low" 2 "Medium_Low" 1 "Medium_High" 0 "High";
VAL_ 310 CAN_DET_CONFID_AZIMUTH_23 3 "Low" 2 "Medium_Low" 1 "Medium_High" 0 "High";
VAL_ 309 CAN_DET_CONFID_AZIMUTH_22 3 "Low" 2 "Medium_Low" 1 "Medium_High" 0 "High";
VAL_ 308 CAN_DET_CONFID_AZIMUTH_21 3 "Low" 2 "Medium_Low" 1 "Medium_High" 0 "High";
VAL_ 307 CAN_DET_CONFID_AZIMUTH_20 3 "Low" 2 "Medium_Low" 1 "Medium_High" 0 "High";
VAL_ 306 CAN_DET_CONFID_AZIMUTH_19 3 "Low" 2 "Medium_Low" 1 "Medium_High" 0 "High";
VAL_ 305 CAN_DET_CONFID_AZIMUTH_18 3 "Low" 2 "Medium_Low" 1 "Medium_High" 0 "High";
VAL_ 341 CAN_DET_CONFID_AZIMUTH_54 3 "Low" 2 "Medium_Low" 1 "Medium_High" 0 "High";
VAL_ 340 CAN_DET_CONFID_AZIMUTH_53 3 "Low" 2 "Medium_Low" 1 "Medium_High" 0 "High";
VAL_ 339 CAN_DET_CONFID_AZIMUTH_52 3 "Low" 2 "Medium_Low" 1 "Medium_High" 0 "High";
VAL_ 338 CAN_DET_CONFID_AZIMUTH_51 3 "Low" 2 "Medium_Low" 1 "Medium_High" 0 "High";
VAL_ 337 CAN_DET_CONFID_AZIMUTH_50 3 "Low" 2 "Medium_Low" 1 "Medium_High" 0 "High";
VAL_ 336 CAN_DET_CONFID_AZIMUTH_49 3 "Low" 2 "Medium_Low" 1 "Medium_High" 0 "High";
VAL_ 326 CAN_DET_CONFID_AZIMUTH_39 3 "Low" 2 "Medium_Low" 1 "Medium_High" 0 "High";
VAL_ 315 CAN_DET_CONFID_AZIMUTH_28 3 "Low" 2 "Medium_Low" 1 "Medium_High" 0 "High";
VAL_ 304 CAN_DET_CONFID_AZIMUTH_17 3 "Low" 2 "Medium_Low" 1 "Medium_High" 0 "High";
VAL_ 303 CAN_DET_CONFID_AZIMUTH_16 3 "Low" 2 "Medium_Low" 1 "Medium_High" 0 "High";
VAL_ 302 CAN_DET_CONFID_AZIMUTH_15 3 "Low" 2 "Medium_Low" 1 "Medium_High" 0 "High";
VAL_ 301 CAN_DET_CONFID_AZIMUTH_14 3 "Low" 2 "Medium_Low" 1 "Medium_High" 0 "High";
VAL_ 300 CAN_DET_CONFID_AZIMUTH_13 3 "Low" 2 "Medium_Low" 1 "Medium_High" 0 "High";
VAL_ 299 CAN_DET_CONFID_AZIMUTH_12 3 "Low" 2 "Medium_Low" 1 "Medium_High" 0 "High";
VAL_ 298 CAN_DET_CONFID_AZIMUTH_11 3 "Low" 2 "Medium_Low" 1 "Medium_High" 0 "High";
VAL_ 297 CAN_DET_CONFID_AZIMUTH_10 3 "Low" 2 "Medium_Low" 1 "Medium_High" 0 "High";
VAL_ 296 CAN_DET_CONFID_AZIMUTH_09 3 "Low" 2 "Medium_Low" 1 "Medium_High" 0 "High";
VAL_ 295 CAN_DET_CONFID_AZIMUTH_08 3 "Low" 2 "Medium_Low" 1 "Medium_High" 0 "High";
VAL_ 294 CAN_DET_CONFID_AZIMUTH_07 3 "Low" 2 "Medium_Low" 1 "Medium_High" 0 "High";
VAL_ 293 CAN_DET_CONFID_AZIMUTH_06 3 "Low" 2 "Medium_Low" 1 "Medium_High" 0 "High";
VAL_ 292 CAN_DET_CONFID_AZIMUTH_05 3 "Low" 2 "Medium_Low" 1 "Medium_High" 0 "High";
VAL_ 290 CAN_DET_CONFID_AZIMUTH_03 3 "Low" 2 "Medium_Low" 1 "Medium_High" 0 "High";
VAL_ 289 CAN_DET_CONFID_AZIMUTH_02 3 "Low" 2 "Medium_Low" 1 "Medium_High" 0 "High";
VAL_ 257 CAN_INTERFERENCE_TYPE 2 "Star PD-Like" 1 "Slow FMCW" 0 "No Interference";
VAL_ 257 CAN_RECOMMEND_UNCONVERGE 1 "Recommended" 0 "Not Recommended";
VAL_ 257 CAN_RADAR_ALIGN_INCOMPLETE 1 "Alignment Incomplete" 0 "Alignment Completed";
VAL_ 257 CAN_BLOCKAGE_SIDELOBE 1 "Radar Blockage" 0 "No Radar Blockage";
VAL_ 257 CAN_BLOCKAGE_MNR 1 "Radar Blockage" 0 "No Radar Blockage";
VAL_ 257 CAN_RADAR_EXT_COND_NOK 1 "Too high temp or insufficient pw" 0 "External conditions OK";
VAL_ 257 CAN_RADAR_ALIGN_OUT_RANGE 1 "Radar out of range" 0 "Radar within range";
VAL_ 257 CAN_RADAR_ALIGN_NOT_START 1 "Radar align not started" 0 "Radar align started";
VAL_ 257 CAN_RADAR_OVERHEAT_ERROR 1 "Radar overheat condition" 0 "No Overheat";
VAL_ 257 CAN_RADAR_NOT_OP 1 "Radar not operational" 0 "Radar operational";
VAL_ 257 CAN_XCVR_OPERATIONAL 1 "On" 0 "Off ";
